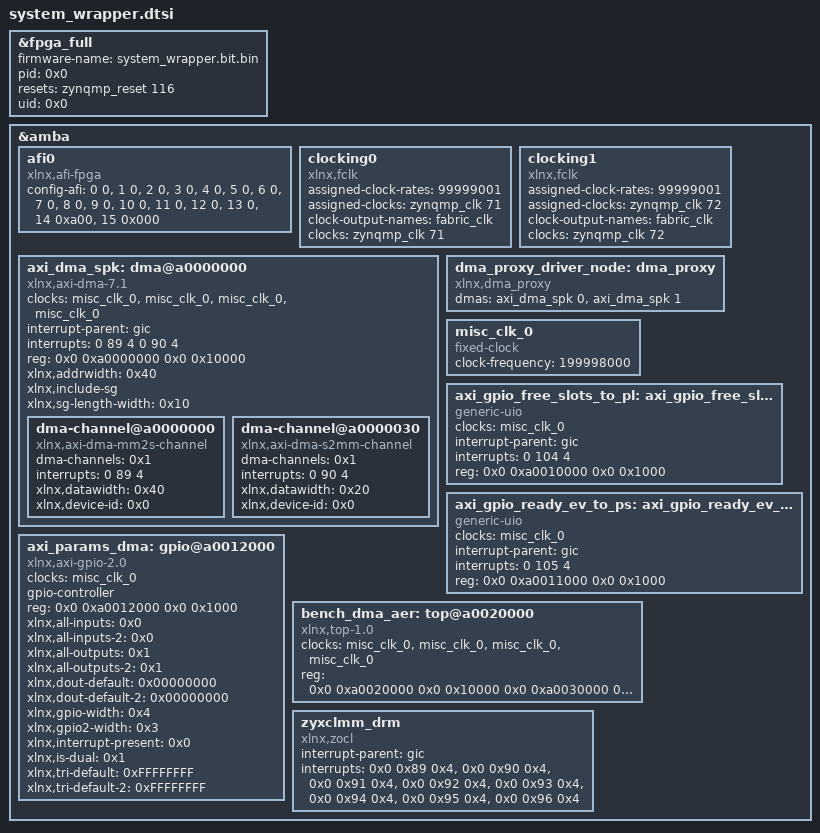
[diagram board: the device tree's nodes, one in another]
/*
 * CAUTION: This file is automatically generated by Xilinx.
 * Version: XSCT 2023.2
 * Today is: Tue Dec 10 14:16:22 2024
 */


/dts-v1/;
/plugin/;
&fpga_full {
	firmware-name = "system_wrapper.bit.bin";
	pid = <0x0>;
	resets = <&zynqmp_reset 116>;
	uid = <0x0>;
};
&amba {
	#address-cells = <2>;
	#size-cells = <2>;
	afi0: afi0 {
		compatible = "xlnx,afi-fpga";
		config-afi = < 0 0>, <1 0>, <2 0>, <3 0>, <4 0>, <5 0>, <6 0>, <7 0>, <8 0>, <9 0>, <10 0>, <11 0>, <12 0>, <13 0>, <14 0xa00>, <15 0x000>;
	};
	clocking0: clocking0 {
		#clock-cells = <0>;
		assigned-clock-rates = <99999001>;
		assigned-clocks = <&zynqmp_clk 71>;
		clock-output-names = "fabric_clk";
		clocks = <&zynqmp_clk 71>;
		compatible = "xlnx,fclk";
	};
	clocking1: clocking1 {
		#clock-cells = <0>;
		assigned-clock-rates = <99999001>;
		assigned-clocks = <&zynqmp_clk 72>;
		clock-output-names = "fabric_clk";
		clocks = <&zynqmp_clk 72>;
		compatible = "xlnx,fclk";
	};
	axi_dma_spk: dma@a0000000 {
		#dma-cells = <1>;
		clock-names = "m_axi_mm2s_aclk", "m_axi_s2mm_aclk", "m_axi_sg_aclk", "s_axi_lite_aclk";
		clocks = <&misc_clk_0>, <&misc_clk_0>, <&misc_clk_0>, <&misc_clk_0>;
		compatible = "xlnx,axi-dma-7.1", "xlnx,axi-dma-1.00.a";
		interrupt-names = "mm2s_introut", "s2mm_introut";
		interrupt-parent = <&gic>;
		interrupts = <0 89 4 0 90 4>;
		reg = <0x0 0xa0000000 0x0 0x10000>;
		xlnx,addrwidth = <0x40>;
		xlnx,include-sg ;
		xlnx,sg-length-width = <0x10>;
		dma-channel@a0000000 {
			compatible = "xlnx,axi-dma-mm2s-channel";
			dma-channels = <0x1>;
			interrupts = <0 89 4>;
			xlnx,datawidth = <0x40>;
			xlnx,device-id = <0x0>;
		};
		dma-channel@a0000030 {
			compatible = "xlnx,axi-dma-s2mm-channel";
			dma-channels = <0x1>;
			interrupts = <0 90 4>;
			xlnx,datawidth = <0x20>;
			xlnx,device-id = <0x0>;
		};
	};
	dma_proxy_driver_node: dma_proxy {
		compatible ="xlnx,dma_proxy";
		dmas = <&axi_dma_spk 0 &axi_dma_spk 1>;
		dma-names = "dma_proxy_spk_to_pl", "dma_proxy_spk_to_ps";
		// dma-coherent;
	};
	misc_clk_0: misc_clk_0 {
		#clock-cells = <0>;
		clock-frequency = <199998000>;
		compatible = "fixed-clock";
	};
	axi_gpio_free_slots_to_pl: axi_gpio_free_slots_to_pl@a0010000 {
		/* This is a place holder node for a custom IP, user may need to update the entries */
		clock-names = "S_AXI_ACLK";
		clocks = <&misc_clk_0>;
		compatible = "generic-uio";
		interrupt-names = "pl_intr";
		interrupt-parent = <&gic>;
		interrupts = <0 104 4>;
		reg = <0x0 0xa0010000 0x0 0x1000>;
	};
	axi_gpio_ready_ev_to_ps: axi_gpio_ready_ev_to_ps@a0011000 {
		/* This is a place holder node for a custom IP, user may need to update the entries */
		clock-names = "S_AXI_ACLK";
		clocks = <&misc_clk_0>;
		compatible = "generic-uio";
		interrupt-names = "pl_intr";
		interrupt-parent = <&gic>;
		interrupts = <0 105 4>;
		reg = <0x0 0xa0011000 0x0 0x1000>;
	};
	axi_params_dma: gpio@a0012000 {
		#gpio-cells = <2>;
		clock-names = "s_axi_aclk";
		clocks = <&misc_clk_0>;
		compatible = "xlnx,axi-gpio-2.0", "xlnx,xps-gpio-1.00.a";
		gpio-controller ;
		reg = <0x0 0xa0012000 0x0 0x1000>;
		xlnx,all-inputs = <0x0>;
		xlnx,all-inputs-2 = <0x0>;
		xlnx,all-outputs = <0x1>;
		xlnx,all-outputs-2 = <0x1>;
		xlnx,dout-default = <0x00000000>;
		xlnx,dout-default-2 = <0x00000000>;
		xlnx,gpio-width = <0x4>;
		xlnx,gpio2-width = <0x3>;
		xlnx,interrupt-present = <0x0>;
		xlnx,is-dual = <0x1>;
		xlnx,tri-default = <0xFFFFFFFF>;
		xlnx,tri-default-2 = <0xFFFFFFFF>;
	};
	bench_dma_aer: top@a0020000 {
		/* This is a place holder node for a custom IP, user may need to update the entries */
		clock-names = "M_AXIS_SPK_MON_ACLK", "S_AXIS_SPK_IN_ACLK", "S_AXI_LITE_CONTROL_ACLK", "S_AXI_LITE_STATUS_ACLK";
		clocks = <&misc_clk_0>, <&misc_clk_0>, <&misc_clk_0>, <&misc_clk_0>;
		compatible = "xlnx,top-1.0";
		reg = <0x0 0xa0020000 0x0 0x10000 0x0 0xa0030000 0x0 0x10000>;
	};
	zyxclmm_drm {
		compatible = "xlnx,zocl";
		interrupt-parent = <&gic>;
		interrupts = <0x0 0x89 0x4>, <0x0 0x90 0x4>, <0x0 0x91 0x4>, <0x0 0x92 0x4>, <0x0 0x93 0x4>, <0x0 0x94 0x4>, <0x0 0x95 0x4>, <0x0 0x96 0x4>;
	};
};
